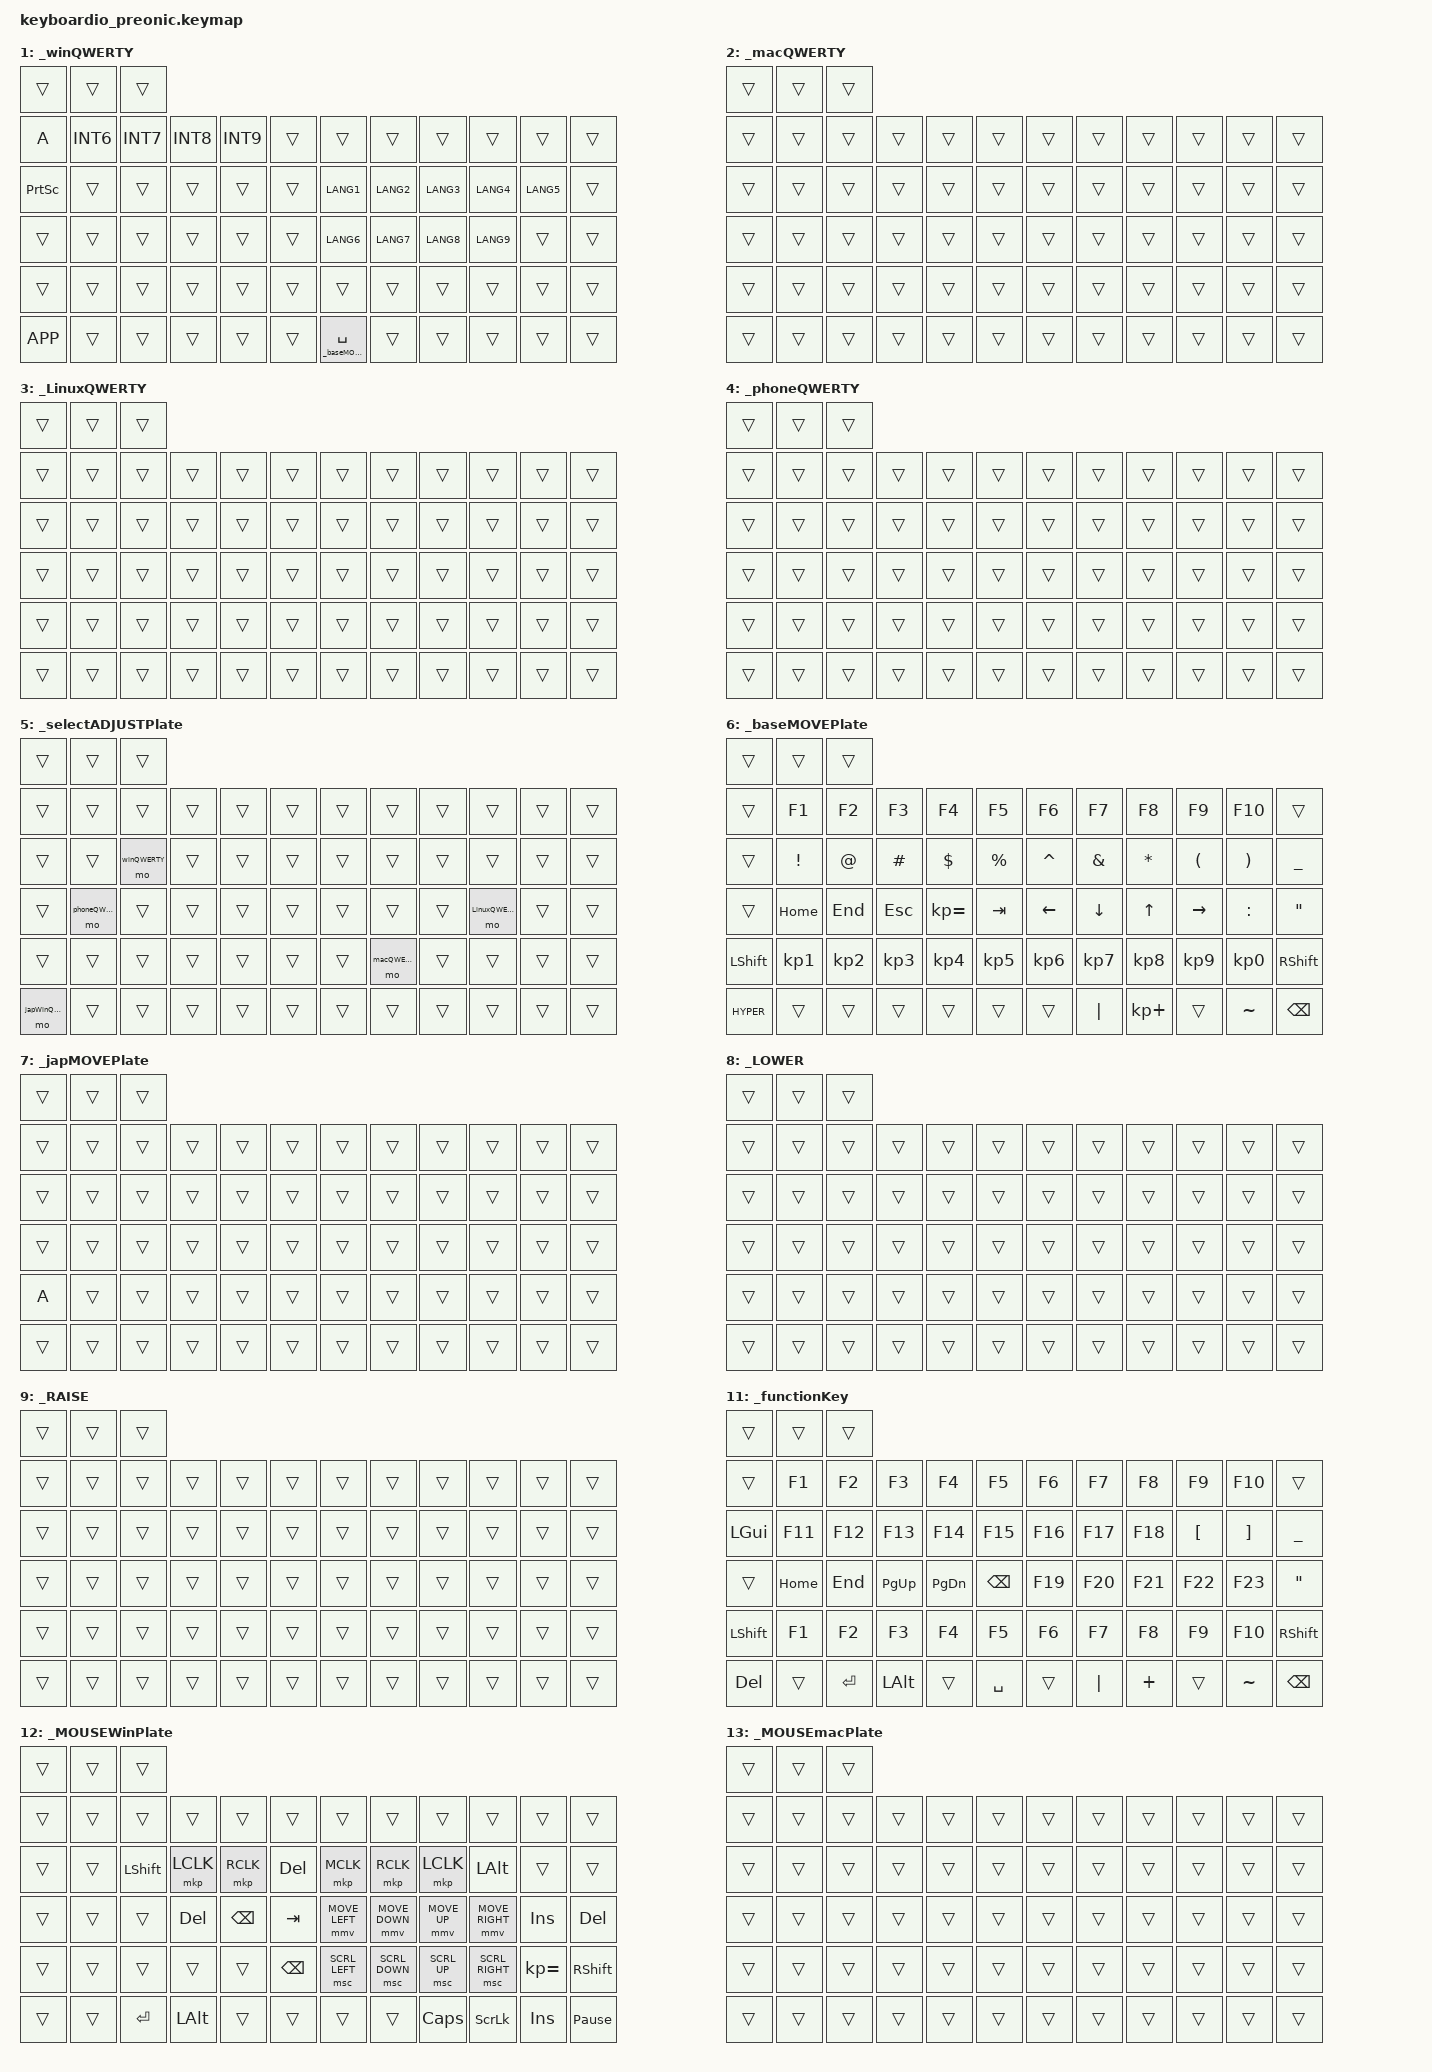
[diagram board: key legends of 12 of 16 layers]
/*
 * Copyright (c) 2022 Pete Johanson
 *
 * SPDX-License-Identifier: MIT
 */

#include <behaviors.dtsi>
#include <dt-bindings/zmk/keys.h>
#include <dt-bindings/zmk/bt.h>	// Bluetooth
#include <dt-bindings/zmk/outputs.h>
#include <dt-bindings/zmk/pointing.h>	// マウスエミュレーション
#include <zephyr/dt-bindings/input/input-event-codes.h>	// バインディング

/*
#define LOWER 1
#define RAISE 2
#define FN 3
enum {
	_japWinQWERTY,
	_winQWERTY,
	_macQWERTY,
	_LinuxQWERTY,
	_phoneQWERTY,
	_baseMOVEPlate,
	_japMOVEPlate,
	_LOWER,
	_RAISE,
	_FUN,
	_MOUSEWinPlate,
	_MOUSEmacPlate,
	_MOUSELinuxPlate,
	_MOUSEphonePlate
};*/
#define	_japWinQWERTY 0
#define	_winQWERTY 1
#define	_macQWERTY 2
#define	_LinuxQWERTY 3
#define	_phoneQWERTY 4
#define	_selectADJUSTPlate 5
#define	_baseMOVEPlate 6
#define	_japMOVEPlate 7
#define	_LOWER 8
#define	_RAISE 9
#define	_Bluetooth_etc 10
#define	_functionKey 11
#define	_MOUSEWinPlate 12
#define	_MOUSEmacPlate 13
#define	_MOUSELinuxPlate 14
#define	_MOUSEphonePlate 15

// Using layer taps on thumbs, having quick tap as well helps w/ repeating space/backspace
&lt { quick_tap_ms = <200>; };

// Convenience macro to make the Bluetooth commands shorter
#define BT(n) BT_SEL n

// Hyper key: all the modifiers
#define HYPER LC(LS(LA(LGUI)))

/ {
	chosen {
		// Valid choices: [ &mit_layout, &ortho_layout ]
		zmk,physical-layout = &mit_layout;
	};

	keymap {
		compatible = "zmk,keymap";


/* WindowsBase Qwerty
 * ,------------------------------------------------------------------------------------------------------------------------.
 * | Delete  |    1    |    2    |    3    |    4    |    5    ||    6    |    7    |    8    |    9    |    0    |BackSpace|
 * |---------+---------+---------+---------+---------+---------++---------+---------+---------+---------+---------+---------|
 * | GUI/Tab |    Q    |    W    |    E    |    R    |    T    ||    Y    |    U    |    I    |    O    |    P    |    -    |
 * |---------+---------+---------+---------+---------+---------++---------+---------+---------+---------+---------+---------|
 * | Ctl/Ent |    A    |    S    |    D    |    F    |    G    ||    H    |    J    |    K    |    L    |    ;    |    '    |
 * |---------+---------+---------+---------+---------+---------++---------+---------+---------+---------+---------+---------|
 * | LShift  |    Z    |    X    |    C    |    V    |    B    ||    N    |    M    |    ,    |    .    |    /    | RShift  |
 * |---------+---------+---------+---------+---------+---------++---------+---------+---------+---------+---------+---------|
 * | HYPER   |LT(MEDIA/BS)|半全角| Alt/del |LT( /Esc)| Ctl/Spc ||LT(/Space|    ¥    |    =    |  Space  |    `    |  Enter  |
 * `------------------------------------------------------------------------------------------------------------------------'
 */

		base_jpLayer {
			label = "_japWinQWERTY";
			bindings = <
   &kp C_PP    &mo _Bluetooth_etc      &kp C_MUTE
   
   &kp DEL   &kp N1   &kp N2   &kp N3   &kp N4   &kp N5		&kp N6   &kp N7   &kp N8   &kp N9   &kp N0   &kp BKSP
   &mt LGUI TAB   &kp Q   &kp W   &kp E   &kp R   &kp T		&kp Y   &kp U   &kp I   &kp O   &kp P   &kp MINUS
   &mt LCTRL ENTER   &kp A   &kp S   &kp D   &kp F   &kp G		&kp H   &kp J   &kp K   &kp L   &kp SEMI   &kp SQT
   &kp LSHFT   &kp Z   &kp X   &kp C   &kp V   &kp B		&kp N   &kp M   &kp COMMA   &kp PERIOD   &kp SLASH   &kp RSHFT
   &kp HYPER   &lt _MOUSEWinPlate BKSP   &kp INT5   &mt LALT DEL   &lt _functionKey ESC   &mt LCTRL SPACE		&lt_MovePlate   &kp SLASH   &kp EQUAL   &kp GRAVE   &kp ENTER
		// LANG1	←☆日本語入力。
		// LANG5	←☆無反応(半角/全角のはずが機能せず)。
		// INT1	←☆無反応(機能せず)。
		// INT2	←☆無反応(機能せず)。
		// INT3	←☆無反応(機能せず)。
		// INT4	←☆無反応(機能せず)。
		// INT5	←☆

			>;
			sensor-bindings = <&inc_dec_kp C_VOLUME_UP C_VOLUME_DOWN>;
		};

		base_winLayer {
			label = "_winQWERTY";
			bindings = <

   &trans  &trans    &trans
   
//   &trans   &trans   &trans   &trans   &trans   &trans		&trans   &trans   &trans   &trans   &trans   &trans
//   &trans   &trans   &trans   &trans   &trans   &trans		&trans   &trans   &trans   &trans   &trans   &trans
//   &trans   &trans   &trans   &trans   &trans   &trans		&trans   &trans   &trans   &trans   &trans   &trans
//   &trans   &trans   &trans   &trans   &trans   &trans		&trans   &trans   &trans   &trans   &trans   &trans
//   &trans   &trans   &trans   &trans   &trans   &trans		&trans   &trans   &trans   &trans   &trans   &trans
   &kp A   &kp INT6   &kp INT7   &kp INT8   &kp INT9   &trans		&trans   &trans   &trans   &trans   &trans   &trans
   &kp PSCRN   &trans   &trans   &trans   &trans   &trans		&kp LANG1   &kp LANG2   &kp LANG3   &kp LANG4   &kp LANG5   &trans
   &trans   &trans   &trans   &trans   &trans   &trans		&kp LANG6   &kp LANG7   &kp LANG8   &kp LANG9   &trans   &trans
   &trans   &trans   &trans   &trans   &trans   &trans		&trans   &trans   &trans   &trans   &trans   &trans
   &kp K_APP   &trans   &trans   &trans   &trans   &trans		&lt _baseMOVEPlate SPACE   &trans   &trans   &trans   &trans   &trans

			>;
			sensor-bindings = <&inc_dec_kp C_VOLUME_UP C_VOLUME_DOWN>;
		};

		base_macLayer {
			label = "_macQWERTY";
			bindings = <

   &trans  &trans    &trans
   
   &trans   &trans   &trans   &trans   &trans   &trans		&trans   &trans   &trans   &trans   &trans   &trans
   &trans   &trans   &trans   &trans   &trans   &trans		&trans   &trans   &trans   &trans   &trans   &trans
   &trans   &trans   &trans   &trans   &trans   &trans		&trans   &trans   &trans   &trans   &trans   &trans
   &trans   &trans   &trans   &trans   &trans   &trans		&trans   &trans   &trans   &trans   &trans   &trans
   &trans   &trans   &trans   &trans   &trans   &trans		&trans   &trans   &trans   &trans   &trans   &trans

			>;
			sensor-bindings = <&inc_dec_kp C_VOLUME_UP C_VOLUME_DOWN>;
		};

		base_linuxLayer {
			label = "_LinuxQWERTY";
			bindings = <

   &trans  &trans    &trans
   
   &trans   &trans   &trans   &trans   &trans   &trans		&trans   &trans   &trans   &trans   &trans   &trans
   &trans   &trans   &trans   &trans   &trans   &trans		&trans   &trans   &trans   &trans   &trans   &trans
   &trans   &trans   &trans   &trans   &trans   &trans		&trans   &trans   &trans   &trans   &trans   &trans
   &trans   &trans   &trans   &trans   &trans   &trans		&trans   &trans   &trans   &trans   &trans   &trans
   &trans   &trans   &trans   &trans   &trans   &trans		&trans   &trans   &trans   &trans   &trans   &trans

			>;
			sensor-bindings = <&inc_dec_kp C_VOLUME_UP C_VOLUME_DOWN>;
		};

		base_phoneLayer {
			label = "_phoneQWERTY";
			bindings = <

   &trans  &trans    &trans
   
   &trans   &trans   &trans   &trans   &trans   &trans		&trans   &trans   &trans   &trans   &trans   &trans
   &trans   &trans   &trans   &trans   &trans   &trans		&trans   &trans   &trans   &trans   &trans   &trans
   &trans   &trans   &trans   &trans   &trans   &trans		&trans   &trans   &trans   &trans   &trans   &trans
   &trans   &trans   &trans   &trans   &trans   &trans		&trans   &trans   &trans   &trans   &trans   &trans
   &trans   &trans   &trans   &trans   &trans   &trans		&trans   &trans   &trans   &trans   &trans   &trans

			>;
			sensor-bindings = <&inc_dec_kp C_VOLUME_UP C_VOLUME_DOWN>;
		};























/* LayerChange and Media Layer
 * ,------------------------------------------------------------------------------------------------------------------------.
 * |         |         |         |         |         |         ||         |         |         |         |         |         |
 * |---------+---------+---------+---------+---------+---------++---------+---------+---------+---------+---------+---------|
 * |         |         |enWinBase|         |         |  10Key  ||         |         |  iOS    | 音楽mode|         |         |
 * |---------+---------+---------+---------+---------+---------++---------+---------+---------+---------+---------+---------|
 * | AudioON | Android | Debug   |         |         |         ||BackSpace|         |  色相増 |  Linux  |  色相減 |         |
 * |---------+---------+---------+---------+---------+---------++---------+---------+---------+---------+---------+---------|
 * | AudioOFF|         |         |         |         |BackSpace|| RollOver|  MacOS  |  彩度上 |         |  彩度下 |         |
 * |---------+---------+---------+---------+---------+---------++---------+---------+---------+---------+---------+---------|
 * |jpWinBase| 配置済み|         | 配置済み| 配置済み|         || 配置済み|         |  明値増 |         |  明値減 |  F12    |
 * `------------------------------------------------------------------------------------------------------------------------'
 */

		plate_selectLayer {
			label = "_selectADJUSTPlate";
			bindings = <

   &trans  &trans    &trans
   
   &trans   &trans   &trans   &trans   &trans   &trans		&trans   &trans   &trans   &trans   &trans   &trans
   &trans   &trans   &mo _winQWERTY   &trans   &trans   &trans		&trans   &trans   &trans   &trans   &trans   &trans
   &trans   &mo _phoneQWERTY   &trans   &trans   &trans   &trans		&trans   &trans   &trans   &mo _LinuxQWERTY   &trans   &trans
   &trans   &trans   &trans   &trans   &trans   &trans		&trans   &mo _macQWERTY   &trans   &trans   &trans   &trans
   &mo _japWinQWERTY   &trans   &trans   &trans   &trans   &trans		&trans   &trans   &trans   &trans   &trans   &trans

			>;
			sensor-bindings = <&inc_dec_kp C_VOLUME_UP C_VOLUME_DOWN>;
		};




























/* Move Layer
 * ,------------------------------------------------------------------------------------------------------------------------.
 * |         |   F1    |   F2    |   F3    |   F4    |   F5    ||   F6    |   F7    |   F8    |   F9    |   F10   |         |
 * |------------------------------------------------------------------------------------------------------------------------.
 * |         |    !    |    @    |    #    |    $    |    %    ||    ^    |    &    |    *    |    (    |    )    |    _    |
 * |---------+---------+---------+---------+---------+---------++---------+---------+---------+---------+---------+---------|
 * |         |   Home  |   End   |   Esc   |    =    |   Tab   ||    ←   |    ↓   |    ↑   |    →   |    :    |    "    |
 * |---------+---------+---------+---------+---------+---------++---------+---------+---------+---------+---------+---------|
 * | LShift  |    1    |    2    |    3    |    4    |    5    ||    6    |    7    |    8    |    9    |    0    | RShift  |
 * |---------+---------+---------+---------+---------+---------++---------+---------+---------+---------+---------+---------|
 * | Hyper   |         |         | 配列済み| 配列済み|         || 配列済み|    |    |    +    |         |    ~    |BackSpace|
 * `------------------------------------------------------------------------------------------------------------------------'
 */

		move_baseLayer {
			label = "_baseMOVEPlate";
			bindings = <

   &trans  &trans    &trans
   
   &trans   &kp F1   &kp F2   &kp F3   &kp F4   &kp F5		&kp F6   &kp F7   &kp F8   &kp F9   &kp F10   &trans
   &trans   &kp EXCL   &kp AT   &kp HASH   &kp DOLLAR   &kp PERCENT		&kp CARET   &kp AMPERSAND   &kp ASTERISK   &kp LPAR   &kp RPAR   &kp UNDER
   &trans   &kp HOME   &kp END   &kp ESC   &kp KP_EQUAL   &kp TAB		&kp LEFT   &kp DOWN   &kp UP   &kp RIGHT   &kp COLON   &kp DQT
   &kp LSHIFT   &kp KP_N1   &kp KP_N2   &kp KP_N3   &kp KP_N4   &kp KP_N5		&kp KP_N6   &kp KP_N7   &kp KP_N8   &kp KP_N9   &kp KP_N0   &kp RSHIFT
   &kp HYPER   &trans   &trans   &trans   &trans   &trans		&trans   &kp PIPE   &kp KP_PLUS   &trans   &kp TILDE   &kp BSPC

			>;
			sensor-bindings = <&inc_dec_kp C_VOLUME_UP C_VOLUME_DOWN>;
		};

		move_jpLayer {
			label = "_japMOVEPlate";
			bindings = <

   &trans  &trans    &trans
   
   &trans   &trans   &trans   &trans   &trans   &trans		&trans   &trans   &trans   &trans   &trans   &trans
   &trans   &trans   &trans   &trans   &trans   &trans		&trans   &trans   &trans   &trans   &trans   &trans
   &trans   &trans   &trans   &trans   &trans   &trans		&trans   &trans   &trans   &trans   &trans   &trans
   &kp A   &trans   &trans   &trans   &trans   &trans		&trans   &trans   &trans   &trans   &trans   &trans
   &trans   &trans   &trans   &trans   &trans   &trans		&trans   &trans   &trans   &trans   &trans   &trans

			>;
			sensor-bindings = <&inc_dec_kp C_VOLUME_UP C_VOLUME_DOWN>;
		};

		lower_layer {
			label = "_LOWER";
			bindings = <

   &trans  &trans    &trans
   
   &trans   &trans   &trans   &trans   &trans   &trans		&trans   &trans   &trans   &trans   &trans   &trans
   &trans   &trans   &trans   &trans   &trans   &trans		&trans   &trans   &trans   &trans   &trans   &trans
   &trans   &trans   &trans   &trans   &trans   &trans		&trans   &trans   &trans   &trans   &trans   &trans
   &trans   &trans   &trans   &trans   &trans   &trans		&trans   &trans   &trans   &trans   &trans   &trans
   &trans   &trans   &trans   &trans   &trans   &trans		&trans   &trans   &trans   &trans   &trans   &trans

			>;
			sensor-bindings = <&inc_dec_kp C_VOLUME_UP C_VOLUME_DOWN>;
		};

		raise_layer {
			label = "_RAISE";
			bindings = <

   &trans  &trans    &trans
   
   &trans   &trans   &trans   &trans   &trans   &trans		&trans   &trans   &trans   &trans   &trans   &trans
   &trans   &trans   &trans   &trans   &trans   &trans		&trans   &trans   &trans   &trans   &trans   &trans
   &trans   &trans   &trans   &trans   &trans   &trans		&trans   &trans   &trans   &trans   &trans   &trans
   &trans   &trans   &trans   &trans   &trans   &trans		&trans   &trans   &trans   &trans   &trans   &trans
   &trans   &trans   &trans   &trans   &trans   &trans		&trans   &trans   &trans   &trans   &trans   &trans

			>;
			sensor-bindings = <&inc_dec_kp C_VOLUME_UP C_VOLUME_DOWN>;
		};


















/* Bluetooth設定など。
 * ,------------------------------------------------------------------------------------------------------------------------.
 * |×blueOFF| blueSel1| blueSel2| blueSel3| blueSel4|×bluePair||        |         |         |         |        |×M(M_ver)|
 * |------------------------------------------------------------------------------------------------------------------------.
 * |LEDeffNext|      |consumerVol++|       |         |         ||         |         |         |         |         |         |
 * |---------+---------+---------+---------+---------+---------++---------+---------+---------+---------+---------+---------|
 * |        |consuTrak--|consuVol--|consuTrak++|     |         ||         |         |         |         |         |         |
 * |---------+---------+---------+---------+---------+---------++---------+---------+---------+---------+---------+---------|
 * |×keyClick|       |consumerMute|       |         |         ||         |         |         |         |         |         |
 * |---------+---------+---------+---------+---------+---------++---------+---------+---------+---------+---------+---------|
 * |M(batteryLev)|     |         | 配列済み| 配列済み|         || 配列済み|         |         |         |         |         |
 * `------------------------------------------------------------------------------------------------------------------------'
 */
 // https://zmk.dev/docs/keymaps/behaviors/bluetooth

		bluetooth_layer {
			label = "_Bluetooth_etc";
			bindings = <

   &trans  &trans    &trans
   
   &trans   &bt BT(1)   &bt BT(2)   &bt BT(3)   &bt BT(4)   &trans		&trans   &trans   &trans   &trans   &trans   &trans
   &trans   &trans   &kp C_VOL_UP   &trans   &trans   &trans		&trans   &trans   &trans   &trans   &trans   &trans
   &trans   &kp C_PREV   &kp C_VOL_DN   &kp C_NEXT   &trans   &trans		&trans   &trans   &trans   &trans   &trans   &trans
   &trans   &trans   &kp C_MUTE   &trans   &trans   &trans		&trans   &trans   &trans   &trans   &trans   &trans
   &trans   &trans   &trans   &trans   &trans   &trans		&trans   &trans   &trans   &trans   &trans   &trans

			>;
			sensor-bindings = <&inc_dec_kp C_VOLUME_UP C_VOLUME_DOWN>;
		};









/* FunctionKey設定など。
 * ,------------------------------------------------------------------------------------------------------------------------.
 * |         |   F1    |   F2    |   F3    |   F4    |   F5    ||   F6    |   F7    |   F8    |   F9    |   F10   |         |
 * |------------------------------------------------------------------------------------------------------------------------.
 * |  GUI    |   F11   |   F12   |   F13   |   F14   |   F15   ||   F16   |   F17   |   F18   |   [     |   ]     |  _      |
 * |---------+---------+---------+---------+---------+---------++---------+---------+---------+---------+---------+---------|
 * |         |  HOME   |  END    |  PageUp |  PgDown |BackSpace||   F19   |   F20   |   F21   |   F22   |   F23   |  "      |
 * |---------+---------+---------+---------+---------+---------++---------+---------+---------+---------+---------+---------|
 * |         |   F1    |   F2    |   F3    |   F4    |   F5    ||   F6    |   F7    |   F8    |   F9    |   F10   |  RShift |
 * |---------+---------+---------+---------+---------+---------++---------+---------+---------+---------+---------+---------|
 * |  Delete | 配置済み|  Enter  |  RAlt   | 配置済み|  Space  || 配置済み|   |     |   +     |         |   ~     |BackSpace|
 * `------------------------------------------------------------------------------------------------------------------------'
 */

		functionKey_layer {
			label = "_functionKey";
			bindings = <

   &trans  &trans    &trans
   
   &trans   &kp F1   &kp F2   &kp F3   &kp F4   &kp F5		&kp F6   &kp F7   &kp F8   &kp F9   &kp F10   &trans
   &kp LGUI   &kp F11   &kp F12   &kp F13   &kp F14   &kp F15		&kp F16   &kp F17   &kp F18   &kp LBKT   &kp RBKT   &kp UNDER
   &trans   &kp HOME   &kp END   &kp PG_UP   &kp PG_DN   &kp BSPC		&kp F19   &kp F20   &kp F21   &kp F22   &kp F23   &kp DQT
   &kp LSHFT   &kp F1   &kp F2   &kp F3   &kp F4   &kp F5		&kp F6   &kp F7   &kp F8   &kp F9   &kp F10   &kp RSHFT
   &kp DEL   &trans   &kp ENTER   &kp LALT   &trans   &kp SPACE		&trans   &kp PIPE   &kp PLUS   &trans   &kp TILDE   &kp BSPC

			>;
			sensor-bindings = <&inc_dec_kp C_VOLUME_UP C_VOLUME_DOWN>;
		};









/* Windows Mouse key
 * ,------------------------------------------------------------------------------------------------------------------------.
 * |         |         |         |         |         |         ||         |         |         |         |         |         |
 * |---------+---------+---------+---------+---------+---------++---------+---------+---------+---------+---------+---------|
 * |         |         | LShift  |  Lclk   |  Rclk   | Delete  || Middle  |  Rclk   |  Lclk   |  RAlt   |PrScrn※1|         |
 * |---------+---------+---------+---------+---------+---------++---------+---------+---------+---------+---------+---------|
 * |         |         | ※PrSc  | Delete  | BSpace  |  Tab    || MsLeft  | MsDown  |  MsUp   | MsRght  | Insert  | Delete  |
 * |---------+---------+---------+---------+---------+---------++---------+---------+---------+---------+---------+---------|
 * |         |         |   cut   |  copy   |  paste  | BSpace  ||  Wleft  | WlDown  | WhelUp  | WRight  |    =    | RShift  |
 * |---------+---------+---------+---------+---------+---------++---------+---------+---------+---------+---------+---------|
 * |         |         |  Enter  |  LAlt※2|         |         ||         |         |CAPSLOCK |SCROLLLOCK| Insert |  PAUSE  |
 * `------------------------------------------------------------------------------------------------------------------------'
 * ※1：	Altキーは独立させておかなければ、WinOSでプリントスクリーン取得に困ることになる。
 * ※2：	通常の場所にAltキーが無ければ不便だと気づいた20200128
 */

		mouse_winLayer {
			label = "_MOUSEWinPlate";
			bindings = <

   &trans  &trans    &trans
   
   &trans   &trans   &trans   &trans   &trans   &trans		&trans   &trans   &trans   &trans   &trans   &trans
   &trans   &trans   &kp LSHIFT   &mkp LCLK   &mkp RCLK   &kp DEL		&mkp MCLK   &mkp RCLK   &mkp LCLK   &kp LALT   &trans   &trans
   &trans   &trans   &trans   &kp DEL   &kp BACKSPACE   &kp TAB		&mmv MOVE_LEFT   &mmv MOVE_DOWN   &mmv MOVE_UP   &mmv MOVE_RIGHT   &kp INSERT   &kp DEL
   &trans   &trans   &trans   &trans   &trans   &kp BACKSPACE		&msc SCRL_LEFT   &msc SCRL_DOWN   &msc SCRL_UP   &msc SCRL_RIGHT   &kp KP_EQUAL   &kp RSHIFT
   &trans   &trans   &kp ENTER   &kp LALT   &trans   &trans		&trans   &trans   &kp CAPSLOCK   &kp SCROLLLOCK   &kp INSERT   &kp PAUSE_BREAK

			>;
			sensor-bindings = <&inc_dec_kp C_VOLUME_UP C_VOLUME_DOWN>;
		};

		mouse_macLayer {
			label = "_MOUSEmacPlate";
			bindings = <

   &trans  &trans    &trans
   
   &trans   &trans   &trans   &trans   &trans   &trans		&trans   &trans   &trans   &trans   &trans   &trans
   &trans   &trans   &trans   &trans   &trans   &trans		&trans   &trans   &trans   &trans   &trans   &trans
   &trans   &trans   &trans   &trans   &trans   &trans		&trans   &trans   &trans   &trans   &trans   &trans
   &trans   &trans   &trans   &trans   &trans   &trans		&trans   &trans   &trans   &trans   &trans   &trans
   &trans   &trans   &trans   &trans   &trans   &trans		&trans   &trans   &trans   &trans   &trans   &trans

			>;
			sensor-bindings = <&inc_dec_kp C_VOLUME_UP C_VOLUME_DOWN>;
		};

		mouse_linuxLayer {
			label = "_MOUSELinuxPlate";
			bindings = <

   &trans  &trans    &trans
   
   &trans   &trans   &trans   &trans   &trans   &trans		&trans   &trans   &trans   &trans   &trans   &trans
   &trans   &trans   &trans   &trans   &trans   &trans		&trans   &trans   &trans   &trans   &trans   &trans
   &trans   &trans   &trans   &trans   &trans   &trans		&trans   &trans   &trans   &trans   &trans   &trans
   &trans   &trans   &trans   &trans   &trans   &trans		&trans   &trans   &trans   &trans   &trans   &trans
   &trans   &trans   &trans   &trans   &trans   &trans		&trans   &trans   &trans   &trans   &trans   &trans

			>;
			sensor-bindings = <&inc_dec_kp C_VOLUME_UP C_VOLUME_DOWN>;
		};

		mouse_phoneLayer {
			label = "_MOUSEphonePlate";
			bindings = <

   &trans  &trans    &trans
   
   &trans   &trans   &trans   &trans   &trans   &trans		&trans   &trans   &trans   &trans   &trans   &trans
   &trans   &trans   &trans   &trans   &trans   &trans		&trans   &trans   &trans   &trans   &trans   &trans
   &trans   &trans   &trans   &trans   &trans   &trans		&trans   &trans   &trans   &trans   &trans   &trans
   &trans   &trans   &trans   &trans   &trans   &trans		&trans   &trans   &trans   &trans   &trans   &trans
   &trans   &trans   &trans   &trans   &trans   &trans		&trans   &trans   &trans   &trans   &trans   &trans

			>;
			sensor-bindings = <&inc_dec_kp C_VOLUME_UP C_VOLUME_DOWN>;
		};










	};

	behaviors {	// botu
		botu_lt_MovePlate: botu_lt_MovePlate {
			compatible = "zmk,behavior-macro";
			#binding-cells = <0>;

			bindings = <
				&mo _baseMOVEPlate
				&mo _japMOVEPlate
			>;
		};

		lt_MovePlate: lt_MovePlate {
			// バインディング	←☆求めていることができない(8/20)。
			//	https://zmk.dev/docs/keymaps/input-processors/behaviors#compatible
//			compatible = "zmk,behavior-multi-mo";
//			compatible = "zmk,behavior-momentary-layer";	// devicetree error: value of property '#binding-cells' on /behaviors/lt_MovePlate in /tmp/tmp.vVB7GsE1jt/zephyr/zephyr.dts.pre (0) is different from the 'const' value specified in /tmp/zmk-config/zmk/app/dts/bindings/behaviors/zmk,behavior-momentary-layer.yaml (1)
//			compatible = "zmk,behavior-macro";	// devicetree error: 'bindings' is marked as required in 'properties:' in /tmp/zmk-config/zmk/app/dts/bindings/behaviors/zmk,behavior-macro.yaml, but does not appear in <Node /behaviors/lt_MovePlate in '/tmp/zmk-config/zephyr/misc/empty_file.c'>
//			compatible = "zmk,behavior-hold-tap";	// devicetree error: 'bindings' is marked as required in 'properties:' in /tmp/zmk-config/zmk/app/dts/bindings/behaviors/zmk,behavior-hold-tap.yaml, but does not appear in <Node /behaviors/lt_MovePlate in '/tmp/zmk-config/zephyr/misc/empty_file.c'>
			compatible = "zmk,input-processor-behaviors";	// devicetree error: binding controller <Node /behaviors/lt_MovePlate in '/tmp/zmk-config/zephyr/misc/empty_file.c'> for <Node /keymap/base_jpLayer in '/tmp/zmk-config/zephyr/misc/empty_file.c'> lacks binding
//例）		#input-processor-cells = <0>;	// devicetree error: '#input-processor-cells' is marked as required in 'properties:' in /tmp/zmk-config/zmk/app/dts/bindings/input_processors/zmk,input-processor-behaviors.yaml, but does not appear in <Node /behaviors/lt_MovePlate in '/tmp/zmk-config/zephyr/misc/empty_file.c'>
//例）		codes    = <INPUT_BTN_1>;	// devicetree error: 'codes' is marked as required in 'properties:' in /tmp/zmk-config/zmk/app/dts/bindings/input_processors/zmk,input-processor-behaviors.yaml, but does not appear in <Node /behaviors/lt_MovePlate in '/tmp/zmk-config/zephyr/misc/empty_file.c'>
//例）		bindings = <&kp LC(V)  >;	// devicetree error: 'bindings' is marked as required in 'properties:' in /tmp/zmk-config/zmk/app/dts/bindings/input_processors/zmk,input-processor-behaviors.yaml, but does not appear in <Node /behaviors/lt_MovePlate in '/tmp/zmk-config/zephyr/misc/empty_file.c'>
			#input-processor-cells = <0>;	// 0固定。
//			codes    = <INPUT_KEY_F23>;
			codes    = <F23>;
			bindings = <&kp F22>;	// これは何のため？
			#binding-cells = <0>;
//err		layers = <_baseMOVEPlate _japMOVEPlate>;	// devicetree error: 'layers' appears in /behaviors/lt_MovePlate in /tmp/tmp.zu3OigabgZ/zephyr/zephyr.dts.pre, but is not declared in 'properties:' in /tmp/zmk-config/zmk/app/dts/bindings/input_processors/zmk,input-processor-behaviors.yaml
		};


		// トリレイヤ。
		conditional_layers {
			compatible = "zmk,conditional-layers";
			tri_layer {
				if-layers = <_MOUSEWinPlate _functionKey>;
				then-layer = <_selectADJUSTPlate>;
			};
		};


	};


};
